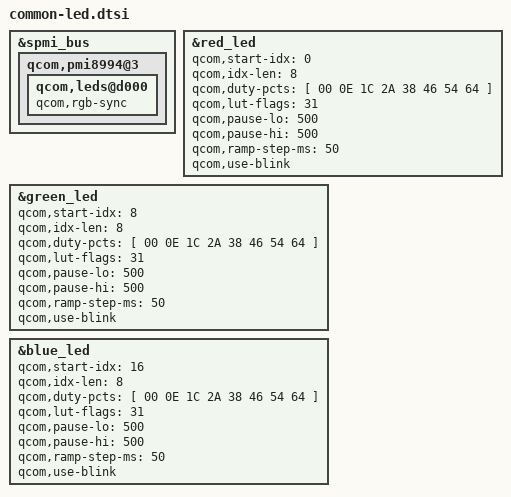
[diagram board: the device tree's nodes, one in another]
&spmi_bus {
	qcom,pmi8994@3 {
		qcom,leds@d000 {
			qcom,rgb-sync;
		};
	};
};

&red_led {
	qcom,start-idx=<0>;
	qcom,idx-len = <8>;
	qcom,duty-pcts=[ 00 0E 1C 2A 38 46 54 64 ];
	qcom,lut-flags=<31>; /* loop, ramp up, reverse, pause hi, pause lo */
	qcom,pause-lo=<500>;
	qcom,pause-hi = <500>;
	qcom,ramp-step-ms = <50>;
	qcom,use-blink;
	/delete-property/ linux,default-trigger;
};

&green_led {
	qcom,start-idx=<8>;
	qcom,idx-len = <8>;
	qcom,duty-pcts=[ 00 0E 1C 2A 38 46 54 64 ];
	qcom,lut-flags=<31>; /* loop, ramp up, reverse, pause hi, pause lo */
	qcom,pause-lo=<500>;
	qcom,pause-hi = <500>;
	qcom,ramp-step-ms = <50>;
	qcom,use-blink;
	/delete-property/ linux,default-trigger;
};

&blue_led {
	qcom,start-idx=<16>;
	qcom,idx-len = <8>;
	qcom,duty-pcts=[ 00 0E 1C 2A 38 46 54 64 ];
	qcom,lut-flags=<31>; /* loop, ramp up, reverse, pause hi, pause lo */
	qcom,pause-lo=<500>;
	qcom,pause-hi = <500>;
	qcom,ramp-step-ms = <50>;
	qcom,use-blink;
	/delete-property/ linux,default-trigger;
};
